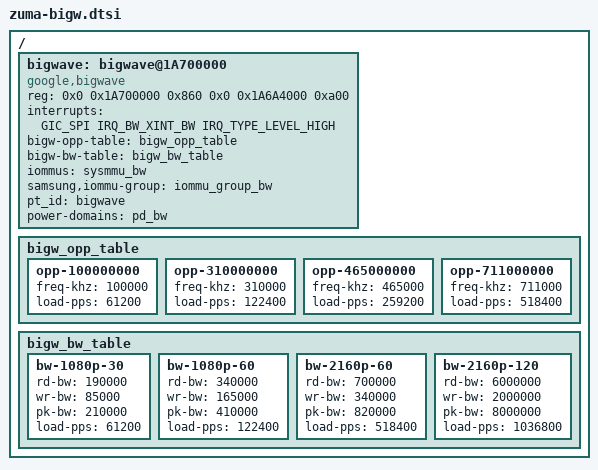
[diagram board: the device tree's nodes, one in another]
// SPDX-License-Identifier: GPL-2.0-only
/*
 * BigWave device tree source
 *
 * Copyright 2022 Google LLC.
 *
 */

/ {
	bigwave: bigwave@1A700000 {
		compatible = "google,bigwave";
		status = "ok";
		reg = <0x0 0x1A700000 0x860
			0x0 0x1A6A4000 0xa00>;
		reg-names = "bw", "ssmt_bw_pid";
		interrupts = <GIC_SPI IRQ_BW_XINT_BW IRQ_TYPE_LEVEL_HIGH>;
		bigw-opp-table = <&bigw_opp_table>;
		bigw-bw-table = <&bigw_bw_table>;
		iommus = <&sysmmu_bw>;
		samsung,iommu-group = <&iommu_group_bw>;
		pt_id = "bigwave";
		power-domains = <&pd_bw>;
	};

	bigw_opp_table: bigw_opp_table {
		opp-100000000 {
			freq-khz = <100000>;
			/* 1920x1088@30fps */
			load-pps = <61200>;
		};
		opp-310000000 {
			freq-khz = <310000>;
			/* 1920x1088@60fps */
			load-pps = <122400>;
		};
		opp-465000000 {
			freq-khz = <465000>;
			/* 4096x2160@30fps */
			load-pps = <259200>;
		};
		opp-711000000 {
			freq-khz = <711000>;
			/* 4096x2160@60fps */
			load-pps = <518400>;
		};
	};

	bigw_bw_table: bigw_bw_table {
		bw-1080p-30 {
			rd-bw = <190000>;
			wr-bw = <85000>;
			pk-bw = <210000>;
			load-pps = <61200>;
		};
		bw-1080p-60 {
			rd-bw = <340000>;
			wr-bw = <165000>;
			pk-bw = <410000>;
			load-pps = <122400>;
		};
		bw-2160p-60 {
			rd-bw = <700000>;
			wr-bw = <340000>;
			pk-bw = <820000>;
			load-pps = <518400>;
		};
		bw-2160p-120 {
			rd-bw = <6000000>;
			wr-bw = <2000000>;
			pk-bw = <8000000>;
			load-pps = <1036800>;
		};
	};
};
